VERSION "1.0"

NS_ :

BS_:

BU_: LogSource CbCANLogMark

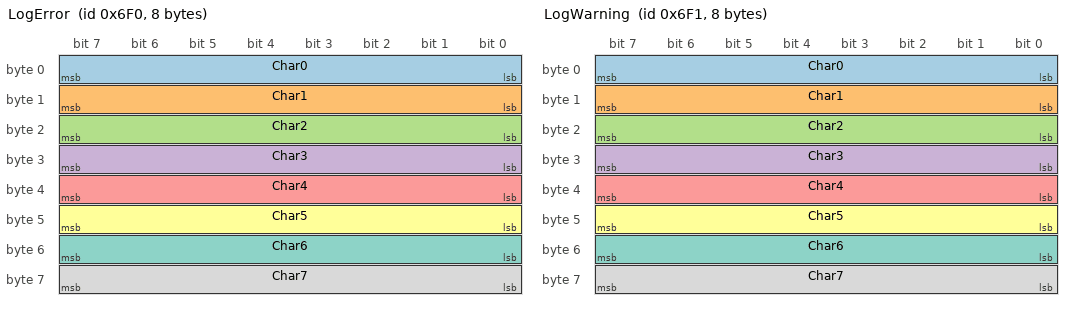
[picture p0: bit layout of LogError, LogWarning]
BO_ 1776 LogError: 8 LogSource
 SG_ Char0 : 0|8@1+ (1,0) [0|255] "" CbCANLogMark
 SG_ Char1 : 8|8@1+ (1,0) [0|255] "" CbCANLogMark
 SG_ Char2 : 16|8@1+ (1,0) [0|255] "" CbCANLogMark
 SG_ Char3 : 24|8@1+ (1,0) [0|255] "" CbCANLogMark
 SG_ Char4 : 32|8@1+ (1,0) [0|255] "" CbCANLogMark
 SG_ Char5 : 40|8@1+ (1,0) [0|255] "" CbCANLogMark
 SG_ Char6 : 48|8@1+ (1,0) [0|255] "" CbCANLogMark
 SG_ Char7 : 56|8@1+ (1,0) [0|255] "" CbCANLogMark

BO_ 1777 LogWarning: 8 LogSource
 SG_ Char0 : 0|8@1+ (1,0) [0|255] "" CbCANLogMark
 SG_ Char1 : 8|8@1+ (1,0) [0|255] "" CbCANLogMark
 SG_ Char2 : 16|8@1+ (1,0) [0|255] "" CbCANLogMark
 SG_ Char3 : 24|8@1+ (1,0) [0|255] "" CbCANLogMark
 SG_ Char4 : 32|8@1+ (1,0) [0|255] "" CbCANLogMark
 SG_ Char5 : 40|8@1+ (1,0) [0|255] "" CbCANLogMark
 SG_ Char6 : 48|8@1+ (1,0) [0|255] "" CbCANLogMark
 SG_ Char7 : 56|8@1+ (1,0) [0|255] "" CbCANLogMark

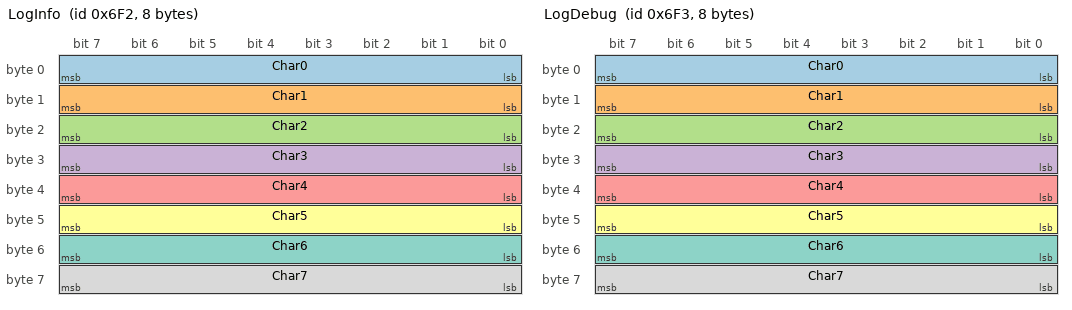
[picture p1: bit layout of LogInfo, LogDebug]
BO_ 1778 LogInfo: 8 LogSource
 SG_ Char0 : 0|8@1+ (1,0) [0|255] "" CbCANLogMark
 SG_ Char1 : 8|8@1+ (1,0) [0|255] "" CbCANLogMark
 SG_ Char2 : 16|8@1+ (1,0) [0|255] "" CbCANLogMark
 SG_ Char3 : 24|8@1+ (1,0) [0|255] "" CbCANLogMark
 SG_ Char4 : 32|8@1+ (1,0) [0|255] "" CbCANLogMark
 SG_ Char5 : 40|8@1+ (1,0) [0|255] "" CbCANLogMark
 SG_ Char6 : 48|8@1+ (1,0) [0|255] "" CbCANLogMark
 SG_ Char7 : 56|8@1+ (1,0) [0|255] "" CbCANLogMark

BO_ 1779 LogDebug: 8 LogSource
 SG_ Char0 : 0|8@1+ (1,0) [0|255] "" CbCANLogMark
 SG_ Char1 : 8|8@1+ (1,0) [0|255] "" CbCANLogMark
 SG_ Char2 : 16|8@1+ (1,0) [0|255] "" CbCANLogMark
 SG_ Char3 : 24|8@1+ (1,0) [0|255] "" CbCANLogMark
 SG_ Char4 : 32|8@1+ (1,0) [0|255] "" CbCANLogMark
 SG_ Char5 : 40|8@1+ (1,0) [0|255] "" CbCANLogMark
 SG_ Char6 : 48|8@1+ (1,0) [0|255] "" CbCANLogMark
 SG_ Char7 : 56|8@1+ (1,0) [0|255] "" CbCANLogMark

CM_ BO_ 1776 "Eight text bytes logged as error; the first NUL byte terminates the text.";
CM_ BO_ 1777 "Eight text bytes logged as warning; the first NUL byte terminates the text.";
CM_ BO_ 1778 "Eight text bytes logged as info; the first NUL byte terminates the text.";
CM_ BO_ 1779 "Eight text bytes logged as debug; the first NUL byte terminates the text.";
